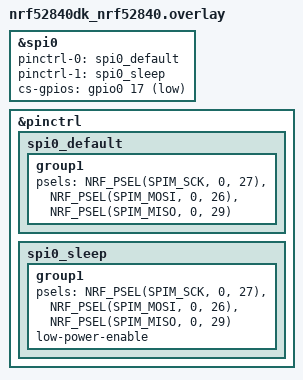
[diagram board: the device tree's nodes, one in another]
&spi0 {
	status = "okay";
	pinctrl-0 = <&spi0_default>;
	pinctrl-1 = <&spi0_sleep>;
	pinctrl-names = "default", "sleep";
	cs-gpios = <&gpio0 17 GPIO_ACTIVE_LOW>;
};

&pinctrl {
	spi0_default: spi0_default {
		group1 {
			psels = <NRF_PSEL(SPIM_SCK, 0, 27)>,
				<NRF_PSEL(SPIM_MOSI, 0, 26)>,
				<NRF_PSEL(SPIM_MISO, 0, 29)>;
		};
	};
	spi0_sleep: spi0_sleep {
		group1 {
			psels = <NRF_PSEL(SPIM_SCK, 0, 27)>,
				<NRF_PSEL(SPIM_MOSI, 0, 26)>,
				<NRF_PSEL(SPIM_MISO, 0, 29)>;
			low-power-enable;
		};
	};
};
